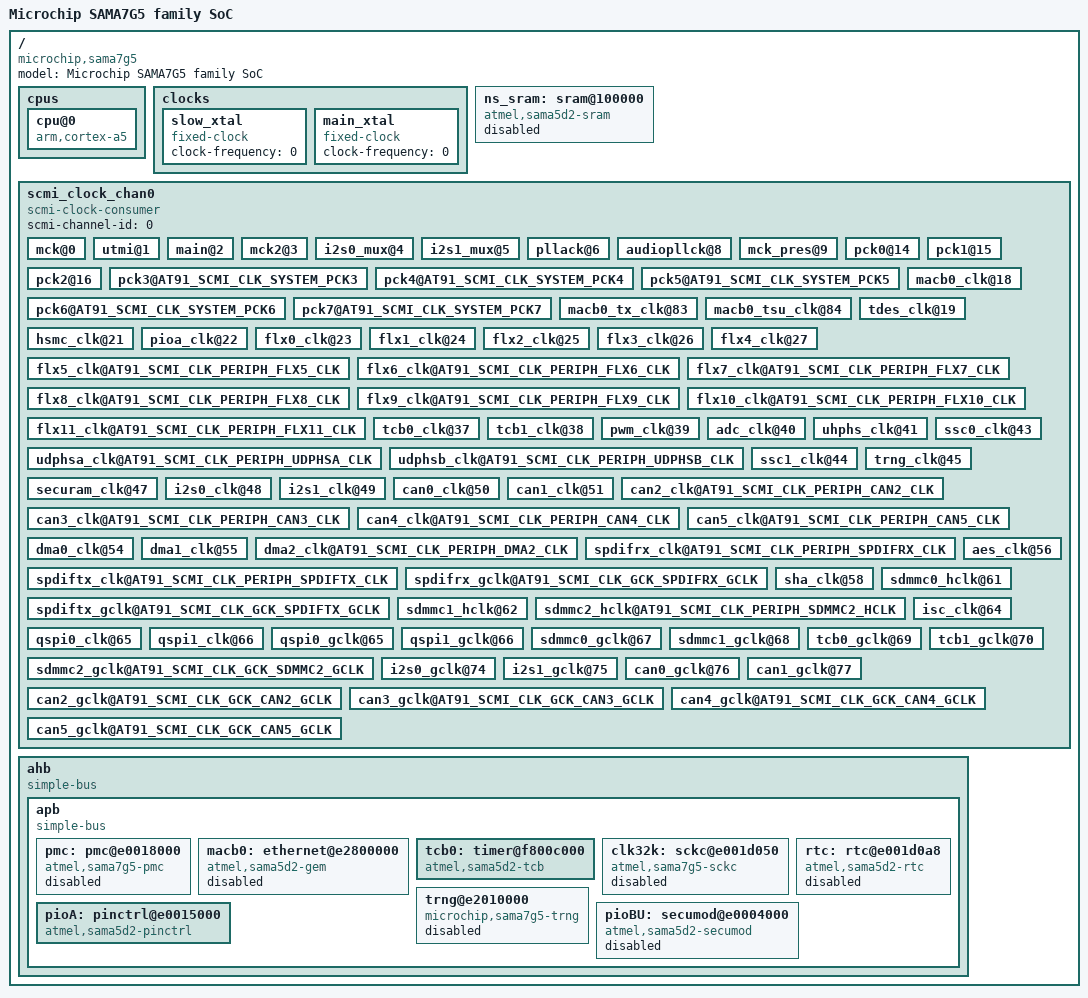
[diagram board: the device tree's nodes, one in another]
// SPDX-License-Identifier: (GPL-2.0+ OR MIT)
/*
 * sama5d2.dtsi - Device Tree Include file for SAMA5D2 family SoC
 *
 *  Copyright (C) 2015 Atmel,
 *                2015 Ludovic Desroches <ludovic.desroches@atmel.com>
 */

#include <dt-bindings/dma/at91.h>
#include <dt-bindings/interrupt-controller/irq.h>
#include <dt-bindings/clock/at91.h>

/ {
	#address-cells = <1>;
	#size-cells = <1>;
	model = "Microchip SAMA7G5 family SoC";
	compatible = "microchip,sama7g5";

	cpus {
		#address-cells = <1>;
		#size-cells = <0>;

		cpu@0 {
			device_type = "cpu";
			compatible = "arm,cortex-a5";
			reg = <0>;
			clocks = <&pmc PMC_TYPE_CORE PMC_MCK_PRES>;
			clock-names = "cpu";
		};
	};

	clocks {
		slow_xtal: slow_xtal {
			compatible = "fixed-clock";
			#clock-cells = <0>;
			clock-frequency = <0>;
		};

		main_xtal: main_xtal {
			compatible = "fixed-clock";
			#clock-cells = <0>;
			clock-frequency = <0>;
		};
	};

	ns_sram: sram@100000 {
		compatible = "atmel,sama5d2-sram", "mmio-sram";
		reg = <0x00100000 0x20000>;
		#address-cells = <1>;
		#size-cells = <1>;
		ranges = <0 0x00100000 0x20000>;
		status = "disabled";
		secure-status = "okay";
	};

	scmi_clock_chan0 {
		compatible = "scmi-clock-consumer";
		#address-cells = <1>;
		#size-cells = <0>;
		scmi-channel-id = <0>;

		mck@0 {
			reg = <AT91_SCMI_CLK_CORE_MCK>;
			clocks = <&pmc PMC_TYPE_CORE PMC_MCK>;
		};
		utmi@1 {
			reg = <AT91_SCMI_CLK_CORE_UTMI>;
			clocks = <&pmc PMC_TYPE_CORE PMC_UTMI>;
		};
		main@2 {
			reg = <AT91_SCMI_CLK_CORE_MAIN>;
			clocks = <&pmc PMC_TYPE_CORE PMC_MAIN>;
		};
		mck2@3 {
			reg = <AT91_SCMI_CLK_CORE_MCK2>;
			clocks = <&pmc PMC_TYPE_CORE PMC_MCK2>;
		};
		i2s0_mux@4 {
			reg = <AT91_SCMI_CLK_CORE_I2S0_MUX>;
			clocks = <&pmc PMC_TYPE_CORE PMC_I2S0_MUX>;
		};
		i2s1_mux@5 {
			reg = <AT91_SCMI_CLK_CORE_I2S1_MUX>;
			clocks = <&pmc PMC_TYPE_CORE PMC_I2S1_MUX>;
		};
		pllack@6 {
			reg = <AT91_SCMI_CLK_CORE_PLLACK>;
			clocks = <&pmc PMC_TYPE_CORE PMC_PLLACK>;
		};
		audiopllck@8 {
			reg = <AT91_SCMI_CLK_CORE_AUDIOPLLCK>;
			clocks = <&pmc PMC_TYPE_CORE PMC_AUDIOPLLCK>;
		};
		mck_pres@9 {
			reg = <AT91_SCMI_CLK_CORE_MCK_PRES>;
			clocks = <&pmc PMC_TYPE_CORE PMC_MCK_PRES>;
		};
		pck0@14 {
			reg = <AT91_SCMI_CLK_SYSTEM_PCK0>;
			clocks = <&pmc PMC_TYPE_SYSTEM 8>;
		};
		pck1@15 {
			reg = <AT91_SCMI_CLK_SYSTEM_PCK1>;
			clocks = <&pmc PMC_TYPE_SYSTEM 9>;
		};
		pck2@16 {
			reg = <AT91_SCMI_CLK_SYSTEM_PCK2>;
			clocks = <&pmc PMC_TYPE_SYSTEM 10>;
		};
		pck3@AT91_SCMI_CLK_SYSTEM_PCK3 { reg = <AT91_SCMI_CLK_SYSTEM_PCK3>; clocks = <&pmc PMC_TYPE_SYSTEM 11>; };
		pck4@AT91_SCMI_CLK_SYSTEM_PCK4 { reg = <AT91_SCMI_CLK_SYSTEM_PCK4>; clocks = <&pmc PMC_TYPE_SYSTEM 12>; };
		pck5@AT91_SCMI_CLK_SYSTEM_PCK5 { reg = <AT91_SCMI_CLK_SYSTEM_PCK5>; clocks = <&pmc PMC_TYPE_SYSTEM 13>; };
		pck6@AT91_SCMI_CLK_SYSTEM_PCK6 { reg = <AT91_SCMI_CLK_SYSTEM_PCK6>; clocks = <&pmc PMC_TYPE_SYSTEM 14>; };
		pck7@AT91_SCMI_CLK_SYSTEM_PCK7 { reg = <AT91_SCMI_CLK_SYSTEM_PCK7>; clocks = <&pmc PMC_TYPE_SYSTEM 15>; };
		macb0_clk@18 {
			reg = <AT91_SCMI_CLK_PERIPH_MACB0_CLK>;
			clocks = <&pmc PMC_TYPE_PERIPHERAL 51>;
		};
		macb0_tx_clk@83 {
			reg = <AT91_SCMI_CLK_GCK_MACB0_GCLK>;
			clocks = <&pmc PMC_TYPE_GCK 51>;
		};
		macb0_tsu_clk@84 {
			reg = <AT91_SCMI_CLK_GCK_MACB0_TSU>;
			clocks = <&pmc PMC_TYPE_GCK 53>;
		};
		tdes_clk@19 {
			reg = <AT91_SCMI_CLK_PERIPH_TDES_CLK>;
			clocks = <&pmc PMC_TYPE_PERIPHERAL 96>;
		};
		hsmc_clk@21 {
			reg = <AT91_SCMI_CLK_PERIPH_HSMC_CLK>;
			clocks = <&pmc PMC_TYPE_PERIPHERAL 21>;
		};
		pioa_clk@22 {
			reg = <AT91_SCMI_CLK_PERIPH_PIOA_CLK>;
			clocks = <&pmc PMC_TYPE_PERIPHERAL 11>;
		};
		flx0_clk@23 {
			reg = <AT91_SCMI_CLK_PERIPH_FLX0_CLK>;
			clocks = <&pmc PMC_TYPE_PERIPHERAL 38>;
		};
		flx1_clk@24 {
			reg = <AT91_SCMI_CLK_PERIPH_FLX1_CLK>;
			clocks = <&pmc PMC_TYPE_PERIPHERAL 39>;
		};
		flx2_clk@25 {
			reg = <AT91_SCMI_CLK_PERIPH_FLX2_CLK>;
			clocks = <&pmc PMC_TYPE_PERIPHERAL 40>;
		};
		flx3_clk@26 {
			reg = <AT91_SCMI_CLK_PERIPH_FLX3_CLK>;
			clocks = <&pmc PMC_TYPE_PERIPHERAL 41>;
		};
		flx4_clk@27 {
			reg = <AT91_SCMI_CLK_PERIPH_FLX4_CLK>;
			clocks = <&pmc PMC_TYPE_PERIPHERAL 42>;
		};
		flx5_clk@AT91_SCMI_CLK_PERIPH_FLX5_CLK { reg = <AT91_SCMI_CLK_PERIPH_FLX5_CLK>; clocks = <&pmc PMC_TYPE_PERIPHERAL 43>; };
		flx6_clk@AT91_SCMI_CLK_PERIPH_FLX6_CLK { reg = <AT91_SCMI_CLK_PERIPH_FLX6_CLK>; clocks = <&pmc PMC_TYPE_PERIPHERAL 44>; };
		flx7_clk@AT91_SCMI_CLK_PERIPH_FLX7_CLK { reg = <AT91_SCMI_CLK_PERIPH_FLX7_CLK>; clocks = <&pmc PMC_TYPE_PERIPHERAL 45>; };
		flx8_clk@AT91_SCMI_CLK_PERIPH_FLX8_CLK { reg = <AT91_SCMI_CLK_PERIPH_FLX8_CLK>; clocks = <&pmc PMC_TYPE_PERIPHERAL 46>; };
		flx9_clk@AT91_SCMI_CLK_PERIPH_FLX9_CLK { reg = <AT91_SCMI_CLK_PERIPH_FLX9_CLK>; clocks = <&pmc PMC_TYPE_PERIPHERAL 47>; };
		flx10_clk@AT91_SCMI_CLK_PERIPH_FLX10_CLK { reg = <AT91_SCMI_CLK_PERIPH_FLX10_CLK>; clocks = <&pmc PMC_TYPE_PERIPHERAL 48>; };
		flx11_clk@AT91_SCMI_CLK_PERIPH_FLX11_CLK { reg = <AT91_SCMI_CLK_PERIPH_FLX11_CLK>; clocks = <&pmc PMC_TYPE_PERIPHERAL 49>; };
		tcb0_clk@37 {
			reg = <AT91_SCMI_CLK_PERIPH_TCB0_CLK>;
			clocks = <&pmc PMC_TYPE_PERIPHERAL 88>;
		};
		tcb1_clk@38 {
			reg = <AT91_SCMI_CLK_PERIPH_TCB1_CLK>;
			clocks = <&pmc PMC_TYPE_PERIPHERAL 91>;
		};
		pwm_clk@39 {
			reg = <AT91_SCMI_CLK_PERIPH_PWM_CLK>;
			clocks = <&pmc PMC_TYPE_PERIPHERAL 77>;
		};
		adc_clk@40 {
			reg = <AT91_SCMI_CLK_PERIPH_ADC_CLK>;
			clocks = <&pmc PMC_TYPE_PERIPHERAL 26>;
		};
		uhphs_clk@41 {
			reg = <AT91_SCMI_CLK_PERIPH_UHPHS_CLK>;
			clocks = <&pmc PMC_TYPE_PERIPHERAL 106>;
		};
		udphsa_clk@AT91_SCMI_CLK_PERIPH_UDPHSA_CLK {
			reg = <AT91_SCMI_CLK_PERIPH_UDPHSA_CLK>;
			clocks = <&pmc PMC_TYPE_PERIPHERAL 104>;
		};
		udphsb_clk@AT91_SCMI_CLK_PERIPH_UDPHSB_CLK {
			reg = <AT91_SCMI_CLK_PERIPH_UDPHSB_CLK>;
			clocks = <&pmc PMC_TYPE_PERIPHERAL 105>;
		};
		ssc0_clk@43 {
			reg = <AT91_SCMI_CLK_PERIPH_SSC0_CLK>;
			clocks = <&pmc PMC_TYPE_PERIPHERAL 86>;
		};
		ssc1_clk@44 {
			reg = <AT91_SCMI_CLK_PERIPH_SSC1_CLK>;
			clocks = <&pmc PMC_TYPE_PERIPHERAL 87>;
		};
		trng_clk@45 {
			reg = <AT91_SCMI_CLK_PERIPH_TRNG_CLK>;
			clocks = <&pmc PMC_TYPE_PERIPHERAL 97>;
		};
		securam_clk@47 {
			reg = <AT91_SCMI_CLK_PERIPH_SECURAM_CLK>;
			clocks = <&pmc PMC_TYPE_PERIPHERAL 18>;
		};
		i2s0_clk@48 {
			reg = <AT91_SCMI_CLK_PERIPH_I2S0_CLK>;
			clocks = <&pmc PMC_TYPE_PERIPHERAL 57>;
		};
		i2s1_clk@49 {
			reg = <AT91_SCMI_CLK_PERIPH_I2S1_CLK>;
			clocks = <&pmc PMC_TYPE_PERIPHERAL 58>;
		};
		can0_clk@50 {
			reg = <AT91_SCMI_CLK_PERIPH_CAN0_CLK>;
			clocks = <&pmc PMC_TYPE_PERIPHERAL 61>;
		};
		can1_clk@51 {
			reg = <AT91_SCMI_CLK_PERIPH_CAN1_CLK>;
			clocks = <&pmc PMC_TYPE_PERIPHERAL 62>;
		};
		can2_clk@AT91_SCMI_CLK_PERIPH_CAN2_CLK { reg = <AT91_SCMI_CLK_PERIPH_CAN2_CLK>; clocks = <&pmc PMC_TYPE_PERIPHERAL 63>; };
		can3_clk@AT91_SCMI_CLK_PERIPH_CAN3_CLK { reg = <AT91_SCMI_CLK_PERIPH_CAN3_CLK>; clocks = <&pmc PMC_TYPE_PERIPHERAL 64>; };
		can4_clk@AT91_SCMI_CLK_PERIPH_CAN4_CLK { reg = <AT91_SCMI_CLK_PERIPH_CAN4_CLK>; clocks = <&pmc PMC_TYPE_PERIPHERAL 65>; };
		can5_clk@AT91_SCMI_CLK_PERIPH_CAN5_CLK { reg = <AT91_SCMI_CLK_PERIPH_CAN5_CLK>; clocks = <&pmc PMC_TYPE_PERIPHERAL 66>; };
		dma0_clk@54 {
			reg = <AT91_SCMI_CLK_PERIPH_DMA0_CLK>;
			clocks = <&pmc PMC_TYPE_PERIPHERAL 22>;
		};
		dma1_clk@55 {
			reg = <AT91_SCMI_CLK_PERIPH_DMA1_CLK>;
			clocks = <&pmc PMC_TYPE_PERIPHERAL 23>;
		};
		dma2_clk@AT91_SCMI_CLK_PERIPH_DMA2_CLK {
			reg = <AT91_SCMI_CLK_PERIPH_DMA2_CLK>;
			clocks = <&pmc PMC_TYPE_PERIPHERAL 24>;
		};
		spdifrx_clk@AT91_SCMI_CLK_PERIPH_SPDIFRX_CLK {
			reg = <AT91_SCMI_CLK_PERIPH_SPDIFRX_CLK>;
			clocks = <&pmc PMC_TYPE_PERIPHERAL 84>;
		};
		spdiftx_clk@AT91_SCMI_CLK_PERIPH_SPDIFTX_CLK {
			reg = <AT91_SCMI_CLK_PERIPH_SPDIFTX_CLK>;
			clocks = <&pmc PMC_TYPE_PERIPHERAL 85>;
		};
		spdifrx_gclk@AT91_SCMI_CLK_GCK_SPDIFRX_GCLK {
			reg = <AT91_SCMI_CLK_GCK_SPDIFRX_GCLK>;
			clocks = <&pmc PMC_TYPE_GCK 84>;
		};
		spdiftx_gclk@AT91_SCMI_CLK_GCK_SPDIFTX_GCLK {
			reg = <AT91_SCMI_CLK_GCK_SPDIFTX_GCLK>;
			clocks = <&pmc PMC_TYPE_GCK 85>;
		};
		aes_clk@56 {
			reg = <AT91_SCMI_CLK_PERIPH_AES_CLK>;
			clocks = <&pmc PMC_TYPE_PERIPHERAL 27>;
		};
		sha_clk@58 {
			reg = <AT91_SCMI_CLK_PERIPH_SHA_CLK>;
			clocks = <&pmc PMC_TYPE_PERIPHERAL 83>;
		};
		sdmmc0_hclk@61 {
			reg = <AT91_SCMI_CLK_PERIPH_SDMMC0_HCLK>;
			clocks = <&pmc PMC_TYPE_PERIPHERAL 80>;
		};
		sdmmc1_hclk@62 {
			reg = <AT91_SCMI_CLK_PERIPH_SDMMC1_HCLK>;
			clocks = <&pmc PMC_TYPE_PERIPHERAL 81>;
		};
		sdmmc2_hclk@AT91_SCMI_CLK_PERIPH_SDMMC2_HCLK {
			reg = <AT91_SCMI_CLK_PERIPH_SDMMC2_HCLK>;
			clocks = <&pmc PMC_TYPE_PERIPHERAL 82>;
		};
		isc_clk@64 {
			reg = <AT91_SCMI_CLK_PERIPH_ISC_CLK>;
			clocks = <&pmc PMC_TYPE_PERIPHERAL 56>;
		};
		qspi0_clk@65 {
			reg = <AT91_SCMI_CLK_PERIPH_QSPI0_CLK>;
			clocks = <&pmc PMC_TYPE_PERIPHERAL 78>;
		};
		qspi1_clk@66 {
			reg = <AT91_SCMI_CLK_PERIPH_QSPI1_CLK>;
			clocks = <&pmc PMC_TYPE_PERIPHERAL 79>;
		};
		qspi0_gclk@65 {
			reg = <AT91_SCMI_CLK_GCK_QSPI0_GCLK>;
			clocks = <&pmc PMC_TYPE_GCK 78>;
		};
		qspi1_gclk@66 {
			reg = <AT91_SCMI_CLK_GCK_QSPI1_GCLK>;
			clocks = <&pmc PMC_TYPE_GCK 79>;
		};
		sdmmc0_gclk@67 {
			reg = <AT91_SCMI_CLK_GCK_SDMMC0_GCLK>;
			clocks = <&pmc PMC_TYPE_GCK 80>;
		};
		sdmmc1_gclk@68 {
			reg = <AT91_SCMI_CLK_GCK_SDMMC1_GCLK>;
			clocks = <&pmc PMC_TYPE_GCK 81>;
		};
		sdmmc2_gclk@AT91_SCMI_CLK_GCK_SDMMC2_GCLK {
			reg = <AT91_SCMI_CLK_GCK_SDMMC2_GCLK>;
			clocks = <&pmc PMC_TYPE_GCK 82>;
		};
		tcb0_gclk@69 {
			reg = <AT91_SCMI_CLK_GCK_TCB0_GCLK>;
			clocks = <&pmc PMC_TYPE_GCK 88>;
		};
		tcb1_gclk@70 {
			reg = <AT91_SCMI_CLK_GCK_TCB1_GCLK>;
			clocks = <&pmc PMC_TYPE_GCK 91>;
		};
		i2s0_gclk@74 {
			reg = <AT91_SCMI_CLK_GCK_I2S0_GCLK>;
			clocks = <&pmc PMC_TYPE_GCK 57>;
		};
		i2s1_gclk@75 {
			reg = <AT91_SCMI_CLK_GCK_I2S1_GCLK>;
			clocks = <&pmc PMC_TYPE_GCK 58>;
		};
		can0_gclk@76 {
			reg = <AT91_SCMI_CLK_GCK_CAN0_GCLK>;
			clocks = <&pmc PMC_TYPE_GCK 61>;
		};
		can1_gclk@77 {
			reg = <AT91_SCMI_CLK_GCK_CAN1_GCLK>;
			clocks = <&pmc PMC_TYPE_GCK 62>;
		};
		can2_gclk@AT91_SCMI_CLK_GCK_CAN2_GCLK { reg = <AT91_SCMI_CLK_GCK_CAN2_GCLK>; clocks = <&pmc PMC_TYPE_GCK 63>; };
		can3_gclk@AT91_SCMI_CLK_GCK_CAN3_GCLK { reg = <AT91_SCMI_CLK_GCK_CAN3_GCLK>; clocks = <&pmc PMC_TYPE_GCK 64>; };
		can4_gclk@AT91_SCMI_CLK_GCK_CAN4_GCLK { reg = <AT91_SCMI_CLK_GCK_CAN4_GCLK>; clocks = <&pmc PMC_TYPE_GCK 65>; };
		can5_gclk@AT91_SCMI_CLK_GCK_CAN5_GCLK { reg = <AT91_SCMI_CLK_GCK_CAN5_GCLK>; clocks = <&pmc PMC_TYPE_GCK 66>; };
	};

	ahb {
		compatible = "simple-bus";
		#address-cells = <1>;
		#size-cells = <1>;
		ranges;

		apb {
			compatible = "simple-bus";
			#address-cells = <1>;
			#size-cells = <1>;
			ranges;

			pmc: pmc@e0018000 {
				compatible = "atmel,sama7g5-pmc", "syscon";
				reg = <0xe0018000 0x100>;
				interrupts = <74 IRQ_TYPE_LEVEL_HIGH 7>;
				#clock-cells = <2>;
				clocks = <&clk32k>, <&main_xtal>;
//				clock-names = "md_slck", "td_slck", "main_xtal";
				clock-names = "md_sclk", "main_xtal";
				status = "disabled";
				secure-status = "okay";
			};

			macb0: ethernet@e2800000 {
				compatible = "atmel,sama5d2-gem";
				reg = <0xe2800000 0x1000>;
				clocks = <&pmc PMC_TYPE_PERIPHERAL 51>, <&pmc PMC_TYPE_PERIPHERAL 51>, <&pmc PMC_TYPE_GCK 51>, <&pmc PMC_TYPE_GCK 53>;
				clock-names = "pclk", "hclk", "tx_clk", "tsu_clk";
				assigned-clocks = <&pmc PMC_TYPE_GCK 51>;
				assigned-clock-parents = <&pmc PMC_TYPE_CORE 11>; /* eth pll div. */
				assigned-clock-rates = <125000000>;
				status = "disabled";
			};

			tcb0: timer@f800c000 {
				compatible = "atmel,sama5d2-tcb", "simple-mfd", "syscon";
				#address-cells = <1>;
				#size-cells = <0>;
				reg = <0xf800c000 0x100>;
				interrupts = <35 IRQ_TYPE_LEVEL_HIGH 0>;
				clocks = <&pmc PMC_TYPE_PERIPHERAL 35>, <&pmc PMC_TYPE_GCK 35>, <&clk32k>;
				clock-names = "t0_clk", "gclk", "md_sclk";
			};
			clk32k: sckc@e001d050 {
				compatible = "atmel,sama7g5-sckc";
				reg = <0xe001d050 0x4>;
//				clocks = <&td_slck>;
				clocks = <&slow_xtal>;
				#clock-cells = <0>;
				status = "disabled";
				secure-status = "okay";
			};

			rtc: rtc@e001d0a8 {
				compatible = "atmel,sama5d2-rtc";
				reg = <0xe001d0a8 0x30>;
				interrupts = <74 IRQ_TYPE_LEVEL_HIGH 7>;
				clocks = <&clk32k>;
				status = "disabled";
				secure-status = "okay";
			};
			trng@e2010000 {
				compatible = "microchip,sama7g5-trng", "atmel,at91sam9g45-trng";
				reg = <0xe2010000 0x100>;
				interrupts = <97 IRQ_TYPE_LEVEL_HIGH 0>;
				clocks = <&pmc PMC_TYPE_PERIPHERAL 97>;
				status = "disabled";
				secure-status = "okay";
			};
			pioA: pinctrl@e0015000 {
				compatible = "atmel,sama5d2-pinctrl";
				reg = <0xe0015000 0x600>;
				interrupts = <11 IRQ_TYPE_LEVEL_HIGH 7>,
					     <12 IRQ_TYPE_LEVEL_HIGH 7>,
					     <13 IRQ_TYPE_LEVEL_HIGH 7>,
					     <14 IRQ_TYPE_LEVEL_HIGH 7>,
					     <15 IRQ_TYPE_LEVEL_HIGH 7>;
				interrupt-controller;
				#interrupt-cells = <2>;
				gpio-controller;
				#gpio-cells = <2>;
				clocks = <&pmc PMC_TYPE_PERIPHERAL 11>;
			};

			pioBU: secumod@e0004000 {
				compatible = "atmel,sama5d2-secumod", "syscon";
				reg = <0xe0004000 0x100>;

				gpio-controller;
				#gpio-cells = <2>;
				status = "disabled";
				secure-status = "okay";
			};
		};
	};
};
